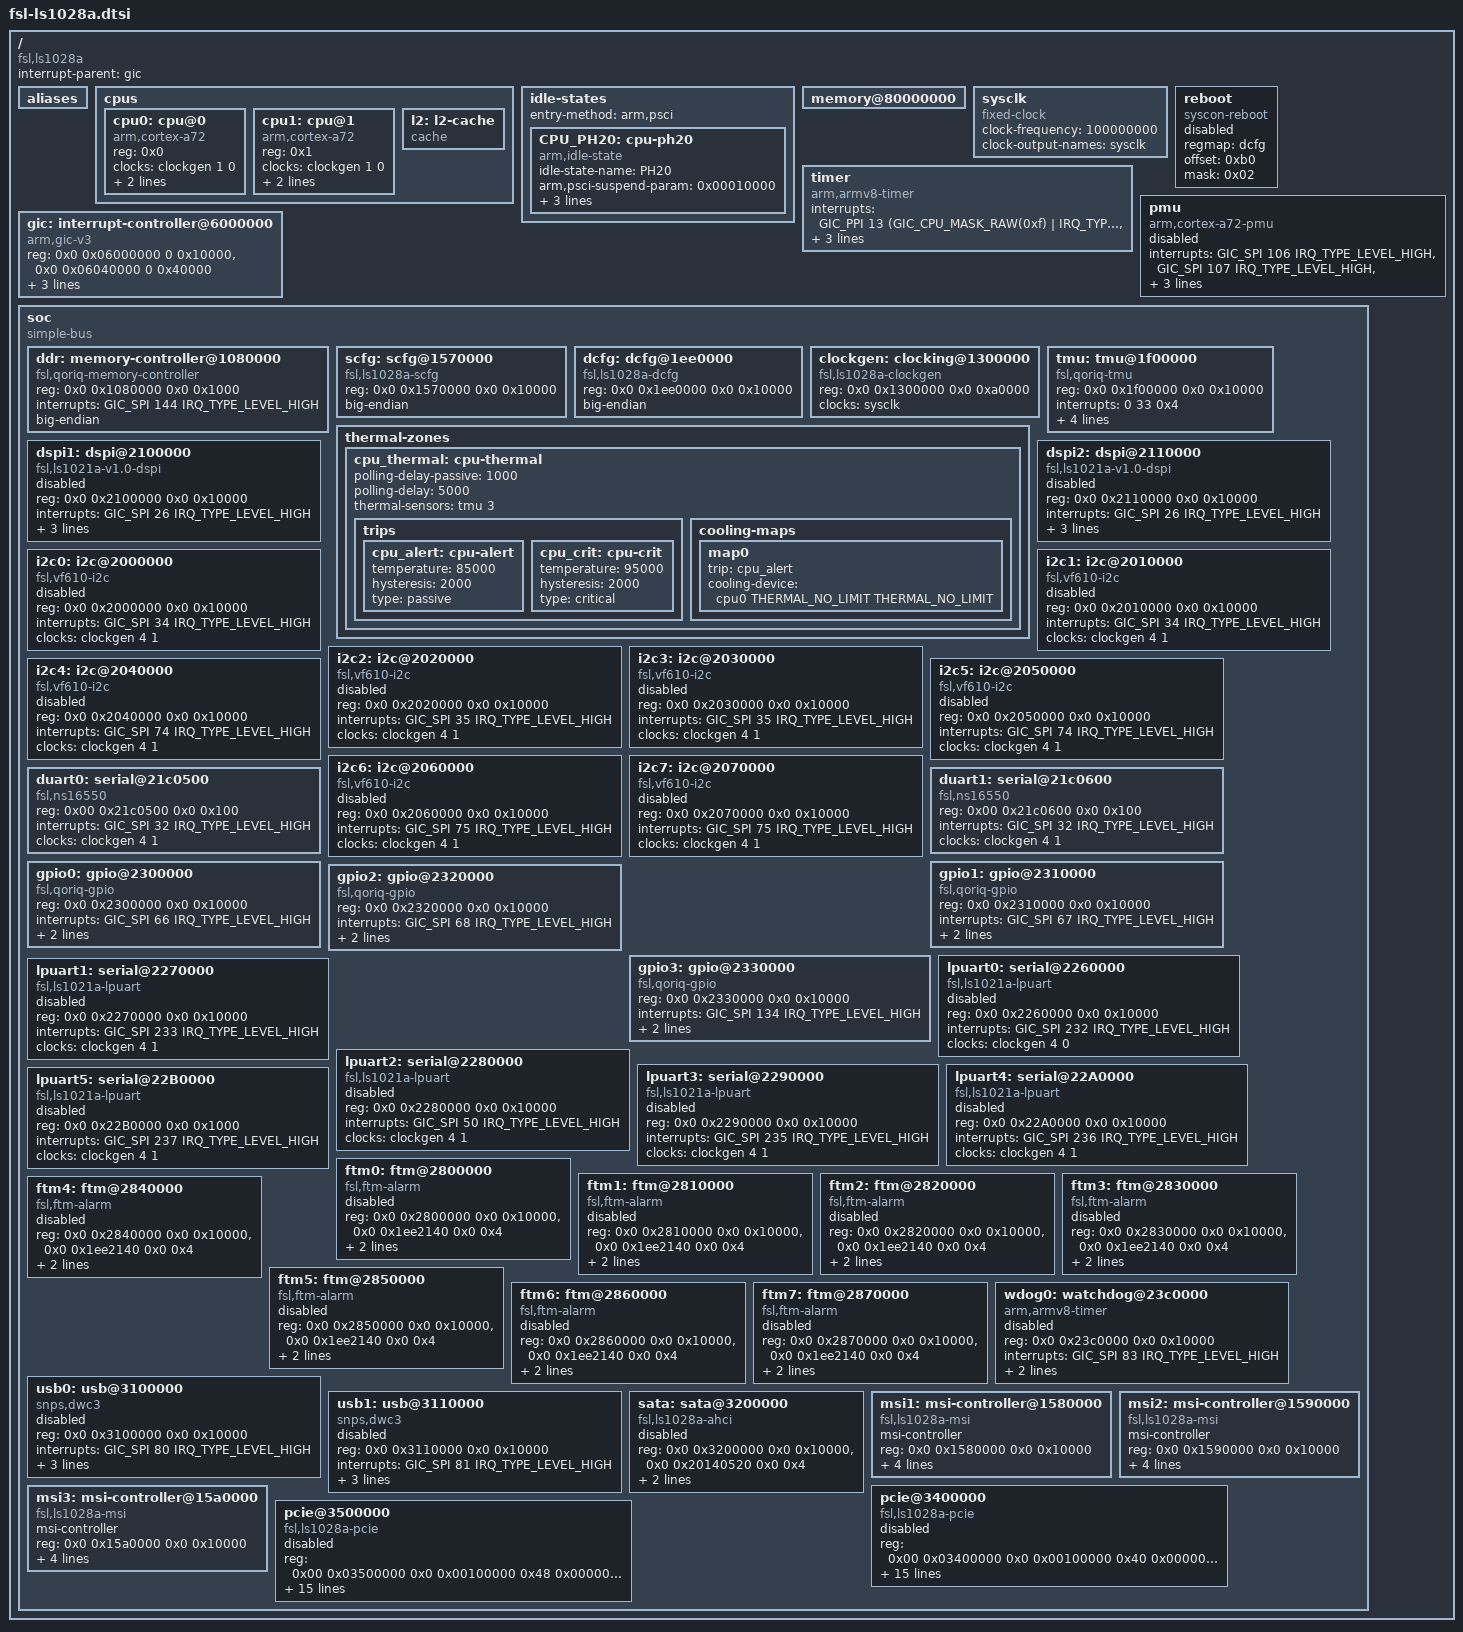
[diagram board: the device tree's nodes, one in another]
/*
 * Device Tree Include file for Freescale Layerscape-1046A family SoC.
 *
 * Copyright 2016 Freescale Semiconductor, Inc.
 *
 * Mingkai Hu <mingkai.hu@nxp.com>
 *
 * This file is dual-licensed: you can use it either under the terms
 * of the GPLv2 or the X11 license, at your option. Note that this dual
 * licensing only applies to this file, and not this project as a
 * whole.
 *
 *  a) This library is free software; you can redistribute it and/or
 *     modify it under the terms of the GNU General Public License as
 *     published by the Free Software Foundation; either version 2 of the
 *     License, or (at your option) any later version.
 *
 *     This library is distributed in the hope that it will be useful,
 *     but WITHOUT ANY WARRANTY; without even the implied warranty of
 *     MERCHANTABILITY or FITNESS FOR A PARTICULAR PURPOSE.  See the
 *     GNU General Public License for more details.
 *
 * Or, alternatively,
 *
 *  b) Permission is hereby granted, free of charge, to any person
 *     obtaining a copy of this software and associated documentation
 *     files (the "Software"), to deal in the Software without
 *     restriction, including without limitation the rights to use,
 *     copy, modify, merge, publish, distribute, sublicense, and/or
 *     sell copies of the Software, and to permit persons to whom the
 *     Software is furnished to do so, subject to the following
 *     conditions:
 *
 *     The above copyright notice and this permission notice shall be
 *     included in all copies or substantial portions of the Software.
 *
 *     THE SOFTWARE IS PROVIDED "AS IS", WITHOUT WARRANTY OF ANY KIND,
 *     EXPRESS OR IMPLIED, INCLUDING BUT NOT LIMITED TO THE WARRANTIES
 *     OF MERCHANTABILITY, FITNESS FOR A PARTICULAR PURPOSE AND
 *     NONINFRINGEMENT. IN NO EVENT SHALL THE AUTHORS OR COPYRIGHT
 *     HOLDERS BE LIABLE FOR ANY CLAIM, DAMAGES OR OTHER LIABILITY,
 *     WHETHER IN AN ACTION OF CONTRACT, TORT OR OTHERWISE, ARISING
 *     FROM, OUT OF OR IN CONNECTION WITH THE SOFTWARE OR THE USE OR
 *     OTHER DEALINGS IN THE SOFTWARE.
 */

#include <dt-bindings/interrupt-controller/arm-gic.h>
#include <dt-bindings/thermal/thermal.h>

/ {
	compatible = "fsl,ls1028a";
	interrupt-parent = <&gic>;
	#address-cells = <2>;
	#size-cells = <2>;

	aliases {
	};

	cpus {
		#address-cells = <1>;
		#size-cells = <0>;

		cpu0: cpu@0 {
			device_type = "cpu";
			compatible = "arm,cortex-a72";
			reg = <0x0>;
			clocks = <&clockgen 1 0>;
			next-level-cache = <&l2>;
			cpu-idle-states = <&CPU_PH20>;
			#cooling-cells = <2>;
		};

		cpu1: cpu@1 {
			device_type = "cpu";
			compatible = "arm,cortex-a72";
			reg = <0x1>;
			clocks = <&clockgen 1 0>;
			next-level-cache = <&l2>;
			cpu-idle-states = <&CPU_PH20>;
		};

		l2: l2-cache {
			compatible = "cache";
		};
	};

	idle-states {
		/*
		 * PSCI node is not added default, U-boot will add missing
		 * parts if it determines to use PSCI.
		 */
		entry-method = "arm,psci";

		CPU_PH20: cpu-ph20 {
			compatible = "arm,idle-state";
			idle-state-name = "PH20";
			arm,psci-suspend-param = <0x00010000>;
			entry-latency-us = <1000>;
			exit-latency-us = <1000>;
			min-residency-us = <3000>;
		};
	};

	memory@80000000 {
		device_type = "memory";
	};

	sysclk: sysclk {
		compatible = "fixed-clock";
		#clock-cells = <0>;
		clock-frequency = <100000000>;
		clock-output-names = "sysclk";
	};

	reboot {
		compatible ="syscon-reboot";
		regmap = <&dcfg>;
		offset = <0xb0>;
		mask = <0x02>;
		status = "disabled";
	};

	timer {
		compatible = "arm,armv8-timer";
		interrupts = <GIC_PPI 13 (GIC_CPU_MASK_RAW(0xf) |
					  IRQ_TYPE_LEVEL_LOW)>,
			     <GIC_PPI 14 (GIC_CPU_MASK_RAW(0xf) |
					  IRQ_TYPE_LEVEL_LOW)>,
			     <GIC_PPI 11 (GIC_CPU_MASK_RAW(0xf) |
					  IRQ_TYPE_LEVEL_LOW)>,
			     <GIC_PPI 10 (GIC_CPU_MASK_RAW(0xf) |
					  IRQ_TYPE_LEVEL_LOW)>;
	};

	pmu {
		compatible = "arm,cortex-a72-pmu";
		interrupts = <GIC_SPI 106 IRQ_TYPE_LEVEL_HIGH>,
			     <GIC_SPI 107 IRQ_TYPE_LEVEL_HIGH>,
			     <GIC_SPI 95 IRQ_TYPE_LEVEL_HIGH>,
			     <GIC_SPI 97 IRQ_TYPE_LEVEL_HIGH>;
		interrupt-affinity = <&cpu0>,
				     <&cpu1>;
		status = "disabled";
	};

	gic: interrupt-controller@6000000 {
		compatible= "arm,gic-v3";
		#address-cells = <2>;
		#size-cells = <2>;
		ranges;
		reg= <0x0 0x06000000 0 0x10000>, /* GIC Dist */
			<0x0 0x06040000 0 0x40000>; /* GIC Redistributor */
		#interrupt-cells= <3>;
		interrupt-controller;
		interrupts = <GIC_PPI 9 (GIC_CPU_MASK_RAW(0xf) |
					 IRQ_TYPE_LEVEL_LOW)>;
	};

	soc: soc {
		compatible = "simple-bus";
		#address-cells = <2>;
		#size-cells = <2>;
		ranges;

		ddr: memory-controller@1080000 {
			compatible = "fsl,qoriq-memory-controller";
			reg = <0x0 0x1080000 0x0 0x1000>;
			interrupts = <GIC_SPI 144 IRQ_TYPE_LEVEL_HIGH>;
			big-endian;
		};

		scfg: scfg@1570000 {
			compatible = "fsl,ls1028a-scfg", "syscon";
			reg = <0x0 0x1570000 0x0 0x10000>;
			big-endian;
		};

		dcfg: dcfg@1ee0000 {
			compatible = "fsl,ls1028a-dcfg", "syscon";
			reg = <0x0 0x1ee0000 0x0 0x10000>;
			big-endian;
		};

		clockgen: clocking@1300000 {
			compatible = "fsl,ls1028a-clockgen";
			reg = <0x0 0x1300000 0x0 0xa0000>;
			#clock-cells = <2>;
			clocks = <&sysclk>;
		};

		tmu: tmu@1f00000 {
			compatible = "fsl,qoriq-tmu";
			reg = <0x0 0x1f00000 0x0 0x10000>;
			interrupts = <0 33 0x4>;
			fsl,tmu-range = <0xb0000 0x9002a 0x6004c 0x30062>;
			fsl,tmu-calibration =
				/* Calibration data group 1 */
				<0x00000000 0x00000026
				0x00000001 0x0000002d
				0x00000002 0x00000032
				0x00000003 0x00000039
				0x00000004 0x0000003f
				0x00000005 0x00000046
				0x00000006 0x0000004d
				0x00000007 0x00000054
				0x00000008 0x0000005a
				0x00000009 0x00000061
				0x0000000a 0x0000006a
				0x0000000b 0x00000071
				/* Calibration data group 2 */
				0x00010000 0x00000025
				0x00010001 0x0000002c
				0x00010002 0x00000035
				0x00010003 0x0000003d
				0x00010004 0x00000045
				0x00010005 0x0000004e
				0x00010006 0x00000057
				0x00010007 0x00000061
				0x00010008 0x0000006b
				0x00010009 0x00000076
				/* Calibration data group 3 */
				0x00020000 0x00000029
				0x00020001 0x00000033
				0x00020002 0x0000003d
				0x00020003 0x00000049
				0x00020004 0x00000056
				0x00020005 0x00000061
				0x00020006 0x0000006d
				/* Calibration data group 4 */
				0x00030000 0x00000021
				0x00030001 0x0000002a
				0x00030002 0x0000003c
				0x00030003 0x0000004e>;
			big-endian;
			#thermal-sensor-cells = <1>;
		};

		thermal-zones {
			cpu_thermal: cpu-thermal {
				polling-delay-passive = <1000>;
				polling-delay = <5000>;
				thermal-sensors = <&tmu 3>;

				trips {
					cpu_alert: cpu-alert {
						temperature = <85000>;
						hysteresis = <2000>;
						type = "passive";
					};

					cpu_crit: cpu-crit {
						temperature = <95000>;
						hysteresis = <2000>;
						type = "critical";
					};
				};

				cooling-maps {
					map0 {
						trip = <&cpu_alert>;
						cooling-device =
							<&cpu0 THERMAL_NO_LIMIT
							THERMAL_NO_LIMIT>;
					};
				};
			};
		};

		dspi1: dspi@2100000 {
			compatible = "fsl,ls1021a-v1.0-dspi";
			#address-cells = <1>;
			#size-cells = <0>;
			reg = <0x0 0x2100000 0x0 0x10000>;
			interrupts = <GIC_SPI 26 IRQ_TYPE_LEVEL_HIGH>;
			clock-names = "dspi";
			clocks = <&clockgen 4 1>;
			spi-num-chipselects = <5>;
			big-endian;
			status = "disabled";
		};

		dspi2: dspi@2110000 {
			compatible = "fsl,ls1021a-v1.0-dspi";
			#address-cells = <1>;
			#size-cells = <0>;
			reg = <0x0 0x2110000 0x0 0x10000>;
			interrupts = <GIC_SPI 26 IRQ_TYPE_LEVEL_HIGH>;
			clock-names = "dspi";
			clocks = <&clockgen 4 1>;
			spi-num-chipselects = <5>;
			big-endian;
			status = "disabled";
		};

		i2c0: i2c@2000000 {
			compatible = "fsl,vf610-i2c";
			#address-cells = <1>;
			#size-cells = <0>;
			reg = <0x0 0x2000000 0x0 0x10000>;
			interrupts = <GIC_SPI 34 IRQ_TYPE_LEVEL_HIGH>;
			clocks = <&clockgen 4 1>;
			dma-names = "tx", "rx";
			status = "disabled";
		};

		i2c1: i2c@2010000 {
			compatible = "fsl,vf610-i2c";
			#address-cells = <1>;
			#size-cells = <0>;
			reg = <0x0 0x2010000 0x0 0x10000>;
			interrupts = <GIC_SPI 34 IRQ_TYPE_LEVEL_HIGH>;
			clocks = <&clockgen 4 1>;
			status = "disabled";
		};

		i2c2: i2c@2020000 {
			compatible = "fsl,vf610-i2c";
			#address-cells = <1>;
			#size-cells = <0>;
			reg = <0x0 0x2020000 0x0 0x10000>;
			interrupts = <GIC_SPI 35 IRQ_TYPE_LEVEL_HIGH>;
			clocks = <&clockgen 4 1>;
			status = "disabled";
		};

		i2c3: i2c@2030000 {
			compatible = "fsl,vf610-i2c";
			#address-cells = <1>;
			#size-cells = <0>;
			reg = <0x0 0x2030000 0x0 0x10000>;
			interrupts = <GIC_SPI 35 IRQ_TYPE_LEVEL_HIGH>;
			clocks = <&clockgen 4 1>;
			status = "disabled";
		};

		i2c4: i2c@2040000 {
			compatible = "fsl,vf610-i2c";
			#address-cells = <1>;
			#size-cells = <0>;
			reg = <0x0 0x2040000 0x0 0x10000>;
			interrupts = <GIC_SPI 74 IRQ_TYPE_LEVEL_HIGH>;
			clocks = <&clockgen 4 1>;
			status = "disabled";
		};

		i2c5: i2c@2050000 {
			compatible = "fsl,vf610-i2c";
			#address-cells = <1>;
			#size-cells = <0>;
			reg = <0x0 0x2050000 0x0 0x10000>;
			interrupts = <GIC_SPI 74 IRQ_TYPE_LEVEL_HIGH>;
			clocks = <&clockgen 4 1>;
			status = "disabled";
		};

		i2c6: i2c@2060000 {
			compatible = "fsl,vf610-i2c";
			#address-cells = <1>;
			#size-cells = <0>;
			reg = <0x0 0x2060000 0x0 0x10000>;
			interrupts = <GIC_SPI 75 IRQ_TYPE_LEVEL_HIGH>;
			clocks = <&clockgen 4 1>;
			status = "disabled";
		};

		i2c7: i2c@2070000 {
			compatible = "fsl,vf610-i2c";
			#address-cells = <1>;
			#size-cells = <0>;
			reg = <0x0 0x2070000 0x0 0x10000>;
			interrupts = <GIC_SPI 75 IRQ_TYPE_LEVEL_HIGH>;
			clocks = <&clockgen 4 1>;
			status = "disabled";
		};


		duart0: serial@21c0500 {
			compatible = "fsl,ns16550", "ns16550a";
			reg = <0x00 0x21c0500 0x0 0x100>;
			interrupts = <GIC_SPI 32 IRQ_TYPE_LEVEL_HIGH>;
			clocks = <&clockgen 4 1>;
		};

		duart1: serial@21c0600 {
			compatible = "fsl,ns16550", "ns16550a";
			reg = <0x00 0x21c0600 0x0 0x100>;
			interrupts = <GIC_SPI 32 IRQ_TYPE_LEVEL_HIGH>;
			clocks = <&clockgen 4 1>;
		};

		gpio0: gpio@2300000 {
			compatible = "fsl,qoriq-gpio";
			reg = <0x0 0x2300000 0x0 0x10000>;
			interrupts = <GIC_SPI 66 IRQ_TYPE_LEVEL_HIGH>;
			gpio-controller;
			#gpio-cells = <2>;
			interrupt-controller;
			#interrupt-cells = <2>;
		};

		gpio1: gpio@2310000 {
			compatible = "fsl,qoriq-gpio";
			reg = <0x0 0x2310000 0x0 0x10000>;
			interrupts = <GIC_SPI 67 IRQ_TYPE_LEVEL_HIGH>;
			gpio-controller;
			#gpio-cells = <2>;
			interrupt-controller;
			#interrupt-cells = <2>;
		};

		gpio2: gpio@2320000 {
			compatible = "fsl,qoriq-gpio";
			reg = <0x0 0x2320000 0x0 0x10000>;
			interrupts = <GIC_SPI 68 IRQ_TYPE_LEVEL_HIGH>;
			gpio-controller;
			#gpio-cells = <2>;
			interrupt-controller;
			#interrupt-cells = <2>;
		};

		gpio3: gpio@2330000 {
			compatible = "fsl,qoriq-gpio";
			reg = <0x0 0x2330000 0x0 0x10000>;
			interrupts = <GIC_SPI 134 IRQ_TYPE_LEVEL_HIGH>;
			gpio-controller;
			#gpio-cells = <2>;
			interrupt-controller;
			#interrupt-cells = <2>;
		};

		lpuart0: serial@2260000 {
			compatible = "fsl,ls1021a-lpuart";
			reg = <0x0 0x2260000 0x0 0x10000>;
			interrupts = <GIC_SPI 232 IRQ_TYPE_LEVEL_HIGH>;
			clocks = <&clockgen 4 0>;
			clock-names = "ipg";
			status = "disabled";
		};

		lpuart1: serial@2270000 {
			compatible = "fsl,ls1021a-lpuart";
			reg = <0x0 0x2270000 0x0 0x10000>;
			interrupts = <GIC_SPI 233 IRQ_TYPE_LEVEL_HIGH>;
			clocks = <&clockgen 4 1>;
			clock-names = "ipg";
			status = "disabled";
		};

		lpuart2: serial@2280000 {
			compatible = "fsl,ls1021a-lpuart";
			reg = <0x0 0x2280000 0x0 0x10000>;
			interrupts = <GIC_SPI 50 IRQ_TYPE_LEVEL_HIGH>;
			clocks = <&clockgen 4 1>;
			clock-names = "ipg";
			status = "disabled";
		};

		lpuart3: serial@2290000 {
			compatible = "fsl,ls1021a-lpuart";
			reg = <0x0 0x2290000 0x0 0x10000>;
			interrupts = <GIC_SPI 235 IRQ_TYPE_LEVEL_HIGH>;
			clocks = <&clockgen 4 1>;
			clock-names = "ipg";
			status = "disabled";
		};

		lpuart4: serial@22A0000 {
			compatible = "fsl,ls1021a-lpuart";
			reg = <0x0 0x22A0000 0x0 0x10000>;
			interrupts = <GIC_SPI 236 IRQ_TYPE_LEVEL_HIGH>;
			clocks = <&clockgen 4 1>;
			clock-names = "ipg";
			status = "disabled";
		};

		lpuart5: serial@22B0000 {
			compatible = "fsl,ls1021a-lpuart";
			reg = <0x0 0x22B0000 0x0 0x1000>;
			interrupts = <GIC_SPI 237 IRQ_TYPE_LEVEL_HIGH>;
			clocks = <&clockgen 4 1>;
			clock-names = "ipg";
			status = "disabled";
		};

		ftm0: ftm@2800000 {
			compatible = "fsl,ftm-alarm";
			reg = <0x0 0x2800000 0x0 0x10000>,
			      <0x0 0x1ee2140 0x0 0x4>;
			reg-names = "ftm", "FlexTimer1";
			interrupts = <GIC_SPI 44 IRQ_TYPE_LEVEL_HIGH>;
			big-endian;
			status = "disabled";
		};

		ftm1: ftm@2810000 {
			compatible = "fsl,ftm-alarm";
			reg = <0x0 0x2810000 0x0 0x10000>,
			      <0x0 0x1ee2140 0x0 0x4>;
			reg-names = "ftm", "FlexTimer2";
			interrupts = <GIC_SPI 45 IRQ_TYPE_LEVEL_HIGH>;
			big-endian;
			status = "disabled";
		};


		ftm2: ftm@2820000 {
			compatible = "fsl,ftm-alarm";
			reg = <0x0 0x2820000 0x0 0x10000>,
			      <0x0 0x1ee2140 0x0 0x4>;
			reg-names = "ftm", "FlexTimer3";
			interrupts = <GIC_SPI 242 IRQ_TYPE_LEVEL_HIGH>;
			big-endian;
			status = "disabled";
		};


		ftm3: ftm@2830000 {
			compatible = "fsl,ftm-alarm";
			reg = <0x0 0x2830000 0x0 0x10000>,
			      <0x0 0x1ee2140 0x0 0x4>;
			reg-names = "ftm", "FlexTimer4";
			interrupts = <GIC_SPI 243 IRQ_TYPE_LEVEL_HIGH>;
			big-endian;
			status = "disabled";
		};


		ftm4: ftm@2840000 {
			compatible = "fsl,ftm-alarm";
			reg = <0x0 0x2840000 0x0 0x10000>,
			      <0x0 0x1ee2140 0x0 0x4>;
			reg-names = "ftm", "FlexTimer5";
			interrupts = <GIC_SPI 244 IRQ_TYPE_LEVEL_HIGH>;
			big-endian;
			status = "disabled";
		};

		ftm5: ftm@2850000 {
			compatible = "fsl,ftm-alarm";
			reg = <0x0 0x2850000 0x0 0x10000>,
			      <0x0 0x1ee2140 0x0 0x4>;
			reg-names = "ftm", "FlexTimer6";
			interrupts = <GIC_SPI 245 IRQ_TYPE_LEVEL_HIGH>;
			big-endian;
			status = "disabled";
		};

		ftm6: ftm@2860000 {
			compatible = "fsl,ftm-alarm";
			reg = <0x0 0x2860000 0x0 0x10000>,
			      <0x0 0x1ee2140 0x0 0x4>;
			reg-names = "ftm", "FlexTimer5";
			interrupts = <GIC_SPI 246 IRQ_TYPE_LEVEL_HIGH>;
			big-endian;
			status = "disabled";
		};

		ftm7: ftm@2870000 {
			compatible = "fsl,ftm-alarm";
			reg = <0x0 0x2870000 0x0 0x10000>,
			      <0x0 0x1ee2140 0x0 0x4>;
			reg-names = "ftm", "FlexTimer6";
			interrupts = <GIC_SPI 247 IRQ_TYPE_LEVEL_HIGH>;
			big-endian;
			status = "disabled";
		};

		wdog0: watchdog@23c0000 {
			compatible= "arm,armv8-timer";
			reg = <0x0 0x23c0000 0x0 0x10000>;
			interrupts = <GIC_SPI 83 IRQ_TYPE_LEVEL_HIGH>;
			clocks = <&clockgen 4 1>;
			big-endian;
			status = "disabled";
		};

		usb0: usb@3100000 {
			compatible = "snps,dwc3";
			reg = <0x0 0x3100000 0x0 0x10000>;
			interrupts = <GIC_SPI 80 IRQ_TYPE_LEVEL_HIGH>;
			dr_mode = "host";
			snps,quirk-frame-length-adjustment = <0x20>;
			snps,dis_rxdet_inp3_quirk;
			status = "disabled";
		};

		usb1: usb@3110000 {
			compatible = "snps,dwc3";
			reg = <0x0 0x3110000 0x0 0x10000>;
			interrupts = <GIC_SPI 81 IRQ_TYPE_LEVEL_HIGH>;
			dr_mode = "host";
			snps,quirk-frame-length-adjustment = <0x20>;
			snps,dis_rxdet_inp3_quirk;
			status = "disabled";
		};

		sata: sata@3200000 {
			compatible = "fsl,ls1028a-ahci";
			reg = <0x0 0x3200000 0x0 0x10000>,
				<0x0 0x20140520 0x0 0x4>;
			reg-names = "ahci", "sata-ecc";
			interrupts = <GIC_SPI 69 IRQ_TYPE_LEVEL_HIGH>;
			clocks = <&clockgen 4 1>;
			status = "disabled";
		};

		msi1: msi-controller@1580000 {
			compatible = "fsl,ls1028a-msi";
			msi-controller;
			reg = <0x0 0x1580000 0x0 0x10000>;
			interrupts = <GIC_SPI 116 IRQ_TYPE_LEVEL_HIGH>,
				     <GIC_SPI 111 IRQ_TYPE_LEVEL_HIGH>,
				     <GIC_SPI 112 IRQ_TYPE_LEVEL_HIGH>,
				     <GIC_SPI 113 IRQ_TYPE_LEVEL_HIGH>;
		};

		msi2: msi-controller@1590000 {
			compatible = "fsl,ls1028a-msi";
			msi-controller;
			reg = <0x0 0x1590000 0x0 0x10000>;
			interrupts = <GIC_SPI 126 IRQ_TYPE_LEVEL_HIGH>,
				     <GIC_SPI 121 IRQ_TYPE_LEVEL_HIGH>,
				     <GIC_SPI 122 IRQ_TYPE_LEVEL_HIGH>,
				     <GIC_SPI 123 IRQ_TYPE_LEVEL_HIGH>;
		};

		msi3: msi-controller@15a0000 {
			compatible = "fsl,ls1028a-msi";
			msi-controller;
			reg = <0x0 0x15a0000 0x0 0x10000>;
			interrupts = <GIC_SPI 160 IRQ_TYPE_LEVEL_HIGH>,
				     <GIC_SPI 155 IRQ_TYPE_LEVEL_HIGH>,
				     <GIC_SPI 156 IRQ_TYPE_LEVEL_HIGH>,
				     <GIC_SPI 157 IRQ_TYPE_LEVEL_HIGH>;
		};

		pcie@3400000 {
			compatible = "fsl,ls1028a-pcie", "snps,dw-pcie";
			reg = <0x00 0x03400000 0x0 0x00100000   /* controller registers */
			       0x40 0x00000000 0x0 0x00002000>; /* configuration space */
			reg-names = "regs", "config";
			interrupts = <GIC_SPI 117 IRQ_TYPE_LEVEL_HIGH>, /* PME interrupt */
				     <GIC_SPI 118 IRQ_TYPE_LEVEL_HIGH>; /* aer interrupt */
			interrupt-names = "pme", "aer";
			#address-cells = <3>;
			#size-cells = <2>;
			device_type = "pci";
			dma-coherent;
			num-lanes = <4>;
			bus-range = <0x0 0xff>;
			ranges = <0x81000000 0x0 0x00000000 0x40 0x00010000 0x0 0x00010000   /* downstream I/O */
				  0x82000000 0x0 0x40000000 0x40 0x40000000 0x0 0x40000000>; /* non-prefetchable memory */
			msi-parent = <&msi1>, <&msi2>, <&msi3>;
			#interrupt-cells = <1>;
			interrupt-map-mask = <0 0 0 7>;
			interrupt-map = <0000 0 0 1 &gic GIC_SPI 110 IRQ_TYPE_LEVEL_HIGH>,
					<0000 0 0 2 &gic GIC_SPI 110 IRQ_TYPE_LEVEL_HIGH>,
					<0000 0 0 3 &gic GIC_SPI 110 IRQ_TYPE_LEVEL_HIGH>,
					<0000 0 0 4 &gic GIC_SPI 110 IRQ_TYPE_LEVEL_HIGH>;
			status = "disabled";
		};

		pcie@3500000 {
			compatible = "fsl,ls1028a-pcie", "snps,dw-pcie";
			reg = <0x00 0x03500000 0x0 0x00100000   /* controller registers */
			       0x48 0x00000000 0x0 0x00002000>; /* configuration space */
			reg-names = "regs", "config";
			interrupts = <GIC_SPI 127 IRQ_TYPE_LEVEL_HIGH>,
				     <GIC_SPI 128 IRQ_TYPE_LEVEL_HIGH>;
			interrupt-names = "pme", "aer";
			#address-cells = <3>;
			#size-cells = <2>;
			device_type = "pci";
			dma-coherent;
			num-lanes = <2>;
			bus-range = <0x0 0xff>;
			ranges = <0x81000000 0x0 0x00000000 0x48 0x00010000 0x0 0x00010000   /* downstream I/O */
				  0x82000000 0x0 0x40000000 0x48 0x40000000 0x0 0x40000000>; /* non-prefetchable memory */
			msi-parent = <&msi1>, <&msi2>, <&msi3>;
			#interrupt-cells = <1>;
			interrupt-map-mask = <0 0 0 7>;
			interrupt-map = <0000 0 0 1 &gic GIC_SPI 120 IRQ_TYPE_LEVEL_HIGH>,
					<0000 0 0 2 &gic GIC_SPI 120 IRQ_TYPE_LEVEL_HIGH>,
					<0000 0 0 3 &gic GIC_SPI 120 IRQ_TYPE_LEVEL_HIGH>,
					<0000 0 0 4 &gic GIC_SPI 120 IRQ_TYPE_LEVEL_HIGH>;
			status = "disabled";
		};

	};

};

